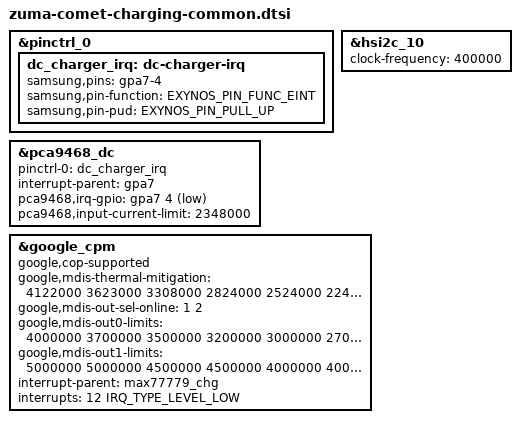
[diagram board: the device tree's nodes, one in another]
// SPDX-License-Identifier: GPL-2.0-only
/*
 * Zuma24 Battery device tree entries
 *
 * Copyright 2023 Google LLC
 *
 */
#include "google-dts-base/zuma-charging.dtsi"

&pinctrl_0 {

	dc_charger_irq: dc-charger-irq {
		samsung,pins = "gpa7-4"; /* XEINT_18 (PLC_INT_L) */
		samsung,pin-function = <EXYNOS_PIN_FUNC_EINT>;
		samsung,pin-pud = <EXYNOS_PIN_PULL_UP>;
	};
};

&hsi2c_10 {

	#address-cells = <1>;
	#size-cells = <0>;
	status = "okay";
	clock-frequency = <400000>;

	#include "google-dts-base/zuma-charge-pump-pca9468.dtsi"
};

&pca9468_dc {
	status = "okay";
	pinctrl-0 = <&dc_charger_irq>;

	interrupt-parent = <&gpa7>;
	pca9468,irq-gpio = <&gpa7 4 GPIO_ACTIVE_LOW>; /* PLC_INT_L */

	pca9468,input-current-limit = <2348000>; /* 4.696A max */
};

&google_cpm {
	google,cop-supported;

	// thermal budgets
	google,mdis-thermal-mitigation =
		<4122000 3623000 3308000 2824000 2524000 2241000
		 1864000 1635000 1319000  932000  632000  344000>;

	// source ONLINE selection criteria
	google,mdis-out-sel-online = <1 2>;
	// PD+main-charger, WLC+main-charger
	google,mdis-out0-limits =
		<4000000 3700000 3500000 3200000 3000000 2700000
		 2500000 2300000 2000000 1500000 1000000  500000
		 1100000 1100000  750000  750000  750000  750000
		  750000  650000  550000  450000  350000  250000>;
	// PPS_CP+pca94xx-mains, // No WLC_CP
	google,mdis-out1-limits =
		<5000000  5000000 4500000 4500000 4000000 4000000
		 3500000  3500000 3000000 2500000 2000000 1000000
		 5000000  5000000 4500000 4500000 4000000 4000000
		 3500000  3500000 3000000 2500000 2000000 1000000>;

	interrupt-parent = <&max77779_chg>;
	interrupts = <12 IRQ_TYPE_LEVEL_LOW>;
};
